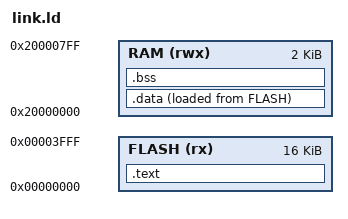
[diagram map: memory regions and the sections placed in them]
/* CH32V003: 16 KB of flash (at 0, aliased from 0x08000000), 2 KB of SRAM. */
MEMORY
{
    FLASH (rx) : ORIGIN = 0x00000000, LENGTH = 16K
    RAM (rwx)  : ORIGIN = 0x20000000, LENGTH = 2K
}

ENTRY(_start)

SECTIONS
{
    .text : {
        KEEP(*(.init))
        *(.text .text.*)
        *(.rodata .rodata.* .srodata .srodata.*)
        . = ALIGN(4);
    } > FLASH

    .data : {
        _sdata = .;
        PROVIDE(__global_pointer$ = . + 0x800);
        *(.data .data.* .sdata .sdata.*)
        . = ALIGN(4);
        _edata = .;
    } > RAM AT > FLASH
    _sidata = LOADADDR(.data);

    .bss (NOLOAD) : {
        _sbss = .;
        *(.bss .bss.* .sbss .sbss.* COMMON)
        . = ALIGN(4);
        _ebss = .;
    } > RAM

    _estack = ORIGIN(RAM) + LENGTH(RAM);
}
